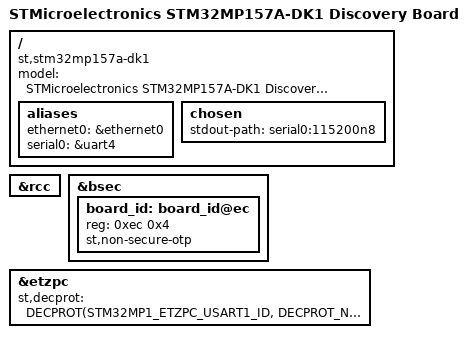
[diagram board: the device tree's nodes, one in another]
// SPDX-License-Identifier: (GPL-2.0+ OR BSD-3-Clause)
/*
 * Copyright (C) STMicroelectronics 2019 - All Rights Reserved
 * Author: Alexandre Torgue <alexandre.torgue@st.com> for STMicroelectronics.
 */

/dts-v1/;

#include "stm32mp157.dtsi"
#include "stm32mp15-pinctrl.dtsi"
#include "stm32mp15xxac-pinctrl.dtsi"
#include "stm32mp15xx-dkx.dtsi"
#include <dt-bindings/soc/stm32mp15-etzpc.h>

/ {
	model = "STMicroelectronics STM32MP157A-DK1 Discovery Board";
	compatible = "st,stm32mp157a-dk1", "st,stm32mp157";

	aliases {
		ethernet0 = &ethernet0;
		serial0 = &uart4;
	};

	chosen {
		stdout-path = "serial0:115200n8";
	};
};

&rcc {
	status = "okay";
};

&bsec {
	board_id: board_id@ec {
		reg = <0xec 0x4>;
		st,non-secure-otp;
	};
};

&etzpc {
	st,decprot = <
		DECPROT(STM32MP1_ETZPC_USART1_ID, DECPROT_NS_RW, DECPROT_UNLOCK)
		DECPROT(STM32MP1_ETZPC_SPI6_ID, DECPROT_NS_RW, DECPROT_UNLOCK)
		DECPROT(STM32MP1_ETZPC_I2C4_ID, DECPROT_NS_RW, DECPROT_UNLOCK)
		DECPROT(STM32MP1_ETZPC_I2C6_ID, DECPROT_NS_RW, DECPROT_UNLOCK)
		DECPROT(STM32MP1_ETZPC_RNG1_ID, DECPROT_S_RW, DECPROT_UNLOCK)
		DECPROT(STM32MP1_ETZPC_HASH1_ID, DECPROT_NS_RW, DECPROT_UNLOCK)
		DECPROT(STM32MP1_ETZPC_DDRCTRL_ID, DECPROT_NS_R_S_W, DECPROT_LOCK)
		DECPROT(STM32MP1_ETZPC_DDRPHYC_ID, DECPROT_NS_R_S_W, DECPROT_LOCK)
		DECPROT(STM32MP1_ETZPC_STGENC_ID, DECPROT_S_RW, DECPROT_LOCK)
		DECPROT(STM32MP1_ETZPC_BKPSRAM_ID, DECPROT_S_RW, DECPROT_LOCK)
		DECPROT(STM32MP1_ETZPC_IWDG1_ID, DECPROT_S_RW, DECPROT_LOCK)
	>;
};
